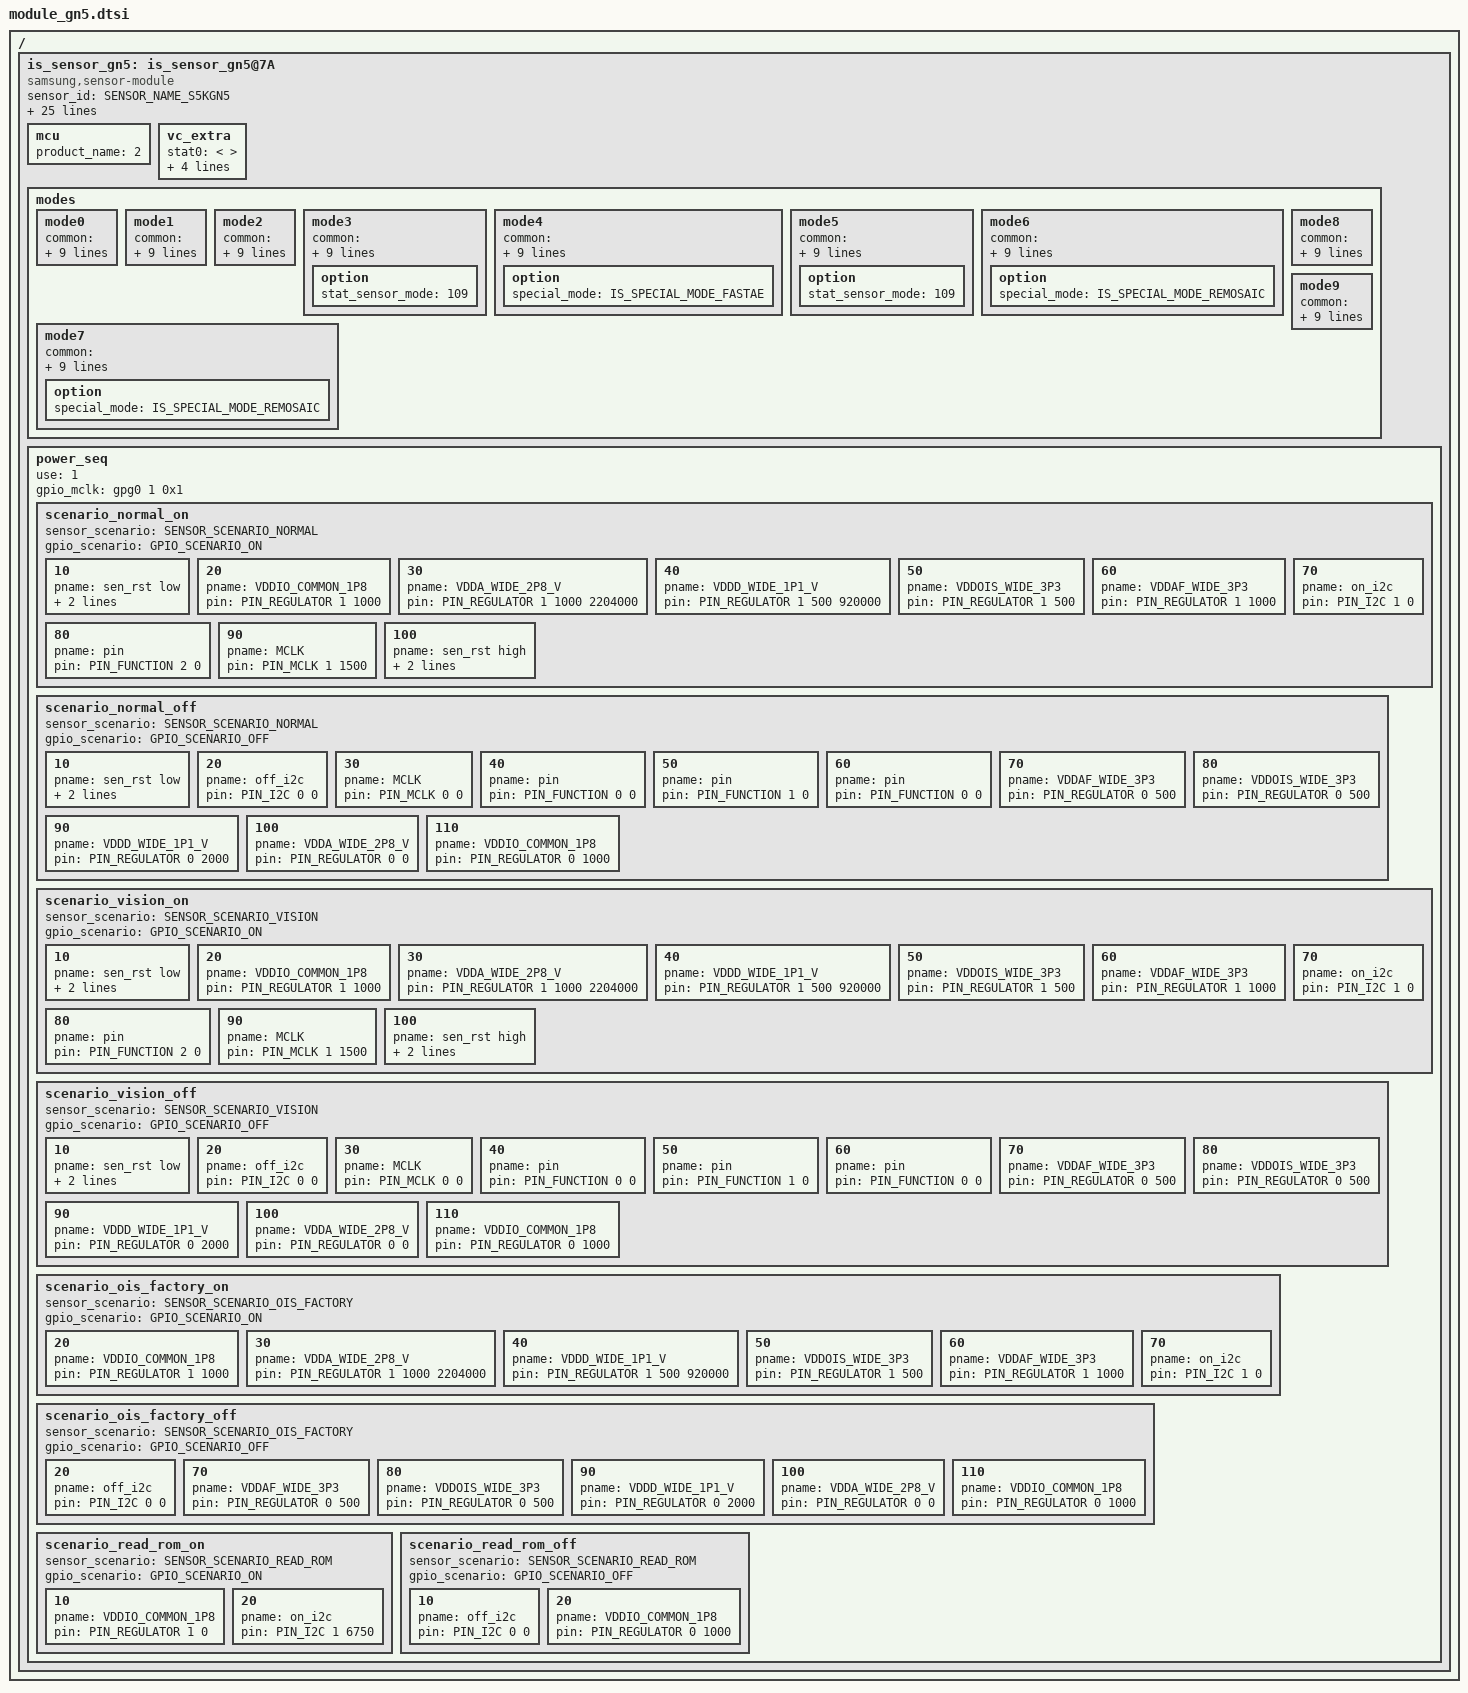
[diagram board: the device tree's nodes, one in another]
/*
 * SAMSUNG EXYNOSxxxx board camera device tree source
 *
 * Copyright (c) 2023 Samsung Electronics Co., Ltd.
 *		http://www.samsung.com
 *
 * This program is free software; you can redistribute it and/or modify
 * it under the terms of the GNU General Public License version 2 as
 * published by the Free Software Foundation.
 */

#include <dt-bindings/camera/exynos_is_dt.h>

/ {
	fragment@camera {
		target-path = "/";
		__overlay__ {
			is_sensor_gn5: is_sensor_gn5@7A {
				compatible = "samsung,sensor-module";

				/* common */
				sensor_id = <SENSOR_NAME_S5KGN5>;
				active_width = <8160>;
				active_height = <6120>;
				margin_left = <0>;
				margin_right = <0>;
				margin_top = <0>;
				margin_bottom = <0>;
				max_framerate = <480>;
				bitwidth = <10>;
				use_retention_mode = <SENSOR_RETENTION_UNSUPPORTED>;
				sensor_maker = "SLSI";
				sensor_name = "S5KGN5";
				setfile_name = "setfile_gn5.bin";

				status = "okay";

				/* board */
				pinctrl-names = "pin0", "pin1", "pin2", "release";
				pinctrl-0 = <>;
				pinctrl-1 = <&sensor_mclk0_out>;
				pinctrl-2 = <&sensor_mclk0_fn>;
				pinctrl-3 = <>;

				position = <0>; /* sensor position of camera dt */
				id = <0>; /* is_sensor id */
				mclk_ch = <0>;
				mclk_freq = <19200>;
				sensor_i2c_ch = <0>; /* SENSOR_CONTROL_I2C0 lock */

				/* vendor */
				rom_type = <2>; /* ROM_TYPE_EEPROM */
				rom_id = <0>;
				rom_cal_index = <0>;

				mcu {
					product_name = <2>; /* MCU_NAME_INTERNAL */
				};

				vc_extra {
					/* ex) statX = <stat_type, sensor_mode, max_width, max_height, max_element> */
					stat0 = </* not available */>;									/* VC_BUF_DATA_TYPE_SENSOR_STAT1 */
					stat1 = </*VC_STAT_TYPE_PDP_4_1_PDAF_STAT0*/ 1200 /*VC_SENSOR_MODE_2PD_MODE3*/ 102 4080 764 2>;	/* VC_BUF_DATA_TYPE_GENERAL_STAT1 */
					stat2 = </* not available */>;									/* VC_BUF_DATA_TYPE_SENSOR_STAT2 */
					stat3 = </*VC_STAT_TYPE_PDP_4_1_PDAF_STAT1*/ 1201 /*VC_SENSOR_MODE_2PD_MODE3*/ 102 4080 764 2>;	/* VC_BUF_DATA_TYPE_GENERAL_STAT2 */
					stat_vc = <2>; /* STAT out VC after CSIS link */
				};

				/* sensor modes
				*	SENSOR_GN5_4080x3060_30FPS 12bit(P) = 0,
				*	SENSOR_GN5_4080x2296_30FPS 12bit(P) = 1,
				*	SENSOR_GN5_4080x2296_60FPS 12bit(P) = 2,
				*	SENSOR_GN5_2040x1532_30FPS 10bit = 3,
				*	SENSOR_GN5_2040x1532_120FPS 10bit = 4,
				*	SENSOR_GN5_2040x1148_240FPS 10bit = 5,
				*	SENSOR_GN5_8160x6120_24FPS 10bit = 6,
				*	SENSOR_GN5_8160x4592_24FPS 10bit = 7,
				*	SENSOR_GN5_4080X3060_30FPS_IDCG_R12 = 8,
				*	SENSOR_GN5_4080X2296_30FPS_IDCG_R12 = 9,
				*/
				modes {
						/* common = <width, height, fps, settle, mode, lane, speed, interleave, lrte, pd_mode> */
						/* vcX = <map, hwformat, width, height, hwformat, type, width, height> */
					mode0 { /* SENSOR_GN5_4080X3060_30FPS_R12 */
						common = <4080 3060 30 0 0 CSI_DATA_LANES_3 2969 CSI_MODE_VC_DT LRTE_ENABLE PD_MOD3 EX_NONE>;
						vc0 = </* in */ 0 HW_FORMAT_RAW12 DATA_IMG 4080 3060    /* out */ HW_FORMAT_RAW12 VC_NOTHING 4080 3060>;
						vc1 = </* in */ 1 HW_FORMAT_UNKNOWN DATA_NONE 0 0        /* out */ HW_FORMAT_UNKNOWN VC_NOTHING 0 0>;
						vc2 = </* in */ 2 HW_FORMAT_RAW10_POTF DATA_HPD 4080 764  /* out */ HW_FORMAT_RAW10 VC_NOTHING 0 0>;
						vc3 = </* in */ 3 HW_FORMAT_UNKNOWN DATA_NONE 0 0        /* out */ HW_FORMAT_UNKNOWN VC_NOTHING 0 0>;
					};
					mode1 { /* SENSOR_GN5_4080X2296_30FPS_R12 */
						common = <4080 2296 30 0 1 CSI_DATA_LANES_3 2969 CSI_MODE_VC_DT LRTE_ENABLE PD_MOD3 EX_NONE>;
						vc0 = </* in */ 0 HW_FORMAT_RAW12 DATA_IMG 4080 2296    /* out */ HW_FORMAT_RAW12 VC_NOTHING 4080 2296>;
						vc1 = </* in */ 1 HW_FORMAT_UNKNOWN DATA_NONE 0 0        /* out */ HW_FORMAT_UNKNOWN VC_NOTHING 0 0>;
						vc2 = </* in */ 2 HW_FORMAT_RAW10_POTF DATA_HPD 4080 574  /* out */ HW_FORMAT_RAW10 VC_NOTHING 0 0>;
						vc3 = </* in */ 3 HW_FORMAT_UNKNOWN DATA_NONE 0 0        /* out */ HW_FORMAT_UNKNOWN VC_NOTHING 0 0>;
					};
					mode2 { /* SENSOR_GN5_4080X2296_60FPS_R12 */
						common = <4080 2296 60 0 2 CSI_DATA_LANES_3 2969 CSI_MODE_VC_DT LRTE_ENABLE PD_MOD3 EX_NONE>;
						vc0 = </* in */ 0 HW_FORMAT_RAW12 DATA_IMG 4080 2296    /* out */ HW_FORMAT_RAW12 VC_NOTHING 4080 2296>;
						vc1 = </* in */ 1 HW_FORMAT_UNKNOWN DATA_NONE 0 0        /* out */ HW_FORMAT_UNKNOWN VC_NOTHING 0 0>;
						vc2 = </* in */ 2 HW_FORMAT_RAW10_POTF DATA_HPD 4080 574  /* out */ HW_FORMAT_RAW10 VC_NOTHING 0 0>;
						vc3 = </* in */ 3 HW_FORMAT_UNKNOWN DATA_NONE 0 0        /* out */ HW_FORMAT_UNKNOWN VC_NOTHING 0 0>;
					};
					mode3 { /* SENSOR_GN5_2040X1532_30FPS_R10 */
						common = <2040 1532 30 0 3 CSI_DATA_LANES_3 2508 CSI_MODE_VC_DT LRTE_ENABLE PD_MOD3 EX_NONE>;
						vc0 = </* in */ 0 HW_FORMAT_RAW10 DATA_IMG 2040 1532    /* out */ HW_FORMAT_RAW10 VC_NOTHING 2040 1532>;
						vc1 = </* in */ 1 HW_FORMAT_UNKNOWN DATA_NONE 0 0        /* out */ HW_FORMAT_UNKNOWN VC_NOTHING 0 0>;
						vc2 = </* in */ 2 HW_FORMAT_RAW10_POTF DATA_HPD 2032 382  /* out */ HW_FORMAT_RAW10 VC_NOTHING 0 0>;
						vc3 = </* in */ 3 HW_FORMAT_UNKNOWN DATA_NONE 0 0        /* out */ HW_FORMAT_UNKNOWN VC_NOTHING 0 0>;
						option { stat_sensor_mode = <109>; };
					};
					mode4 { /* SENSOR_GN5_2040X1532_120FPS_R10 */
						common = <2040 1532 120 0 4 CSI_DATA_LANES_3 2508 CSI_MODE_VC_DT LRTE_ENABLE PD_NONE EX_NONE>;
						vc0 = </* in */ 0 HW_FORMAT_RAW10 DATA_IMG 2040 1532    /* out */ HW_FORMAT_RAW10 VC_NOTHING 2040 1532>;
						vc1 = </* in */ 1 HW_FORMAT_UNKNOWN DATA_NONE 0 0        /* out */ HW_FORMAT_UNKNOWN VC_NOTHING 0 0>;
						vc2 = </* in */ 2 HW_FORMAT_UNKNOWN DATA_NONE 0 0    /* out */ HW_FORMAT_UNKNOWN VC_NOTHING 0 0>;
						vc3 = </* in */ 3 HW_FORMAT_UNKNOWN DATA_NONE 0 0        /* out */ HW_FORMAT_UNKNOWN VC_NOTHING 0 0>;
						option { special_mode = <IS_SPECIAL_MODE_FASTAE>; };
					};
					mode5 { /* SENSOR_GN5_2040X1148_240FPS_R10 */
						common = <2040 1148 240 0 5 CSI_DATA_LANES_3 2508 CSI_MODE_VC_DT LRTE_ENABLE PD_MOD3 EX_NONE>;
						vc0 = </* in */ 0 HW_FORMAT_RAW10 DATA_IMG 2040 1148    /* out */ HW_FORMAT_RAW10 VC_NOTHING 2040 1148>;
						vc1 = </* in */ 1 HW_FORMAT_UNKNOWN DATA_NONE 0 0        /* out */ HW_FORMAT_UNKNOWN VC_NOTHING 0 0>;
						vc2 = </* in */ 2 HW_FORMAT_RAW10_POTF DATA_HPD 2032 286  /* out */ HW_FORMAT_RAW10 VC_NOTHING 0 0>;
						vc3 = </* in */ 3 HW_FORMAT_UNKNOWN DATA_NONE 0 0        /* out */ HW_FORMAT_UNKNOWN VC_NOTHING 0 0>;
						option { stat_sensor_mode = <109>; };
					};
					mode6 { /* SENSOR_GN5_8160X6120_24FPS */
						common = <8160 6120 24 0 6 CSI_DATA_LANES_3 2969 CSI_MODE_VC_DT LRTE_ENABLE PD_NONE EX_NONE>;
						vc0 = </* in */ 0 HW_FORMAT_RAW10 DATA_IMG 8160 6120    /* out */ HW_FORMAT_RAW10 VC_NOTHING 8160 6120>;
						vc1 = </* in */ 1 HW_FORMAT_UNKNOWN DATA_NONE 0 0        /* out */ HW_FORMAT_UNKNOWN VC_NOTHING 0 0>;
						vc2 = </* in */ 2 HW_FORMAT_UNKNOWN DATA_NONE 0 0    /* out */ HW_FORMAT_UNKNOWN VC_NOTHING 0 0>;
						vc3 = </* in */ 3 HW_FORMAT_UNKNOWN DATA_NONE 0 0        /* out */ HW_FORMAT_UNKNOWN VC_NOTHING 0 0>;
						option { special_mode = <IS_SPECIAL_MODE_REMOSAIC>; };
					};
					mode7 { /* SENSOR_GN5_8160X4592_24FPS */
						common = <8160 4592 24 0 7 CSI_DATA_LANES_3 2969 CSI_MODE_VC_DT LRTE_ENABLE PD_NONE EX_NONE>;
						vc0 = </* in */ 0 HW_FORMAT_RAW10 DATA_IMG 8160 4592    /* out */ HW_FORMAT_RAW10 VC_NOTHING 8160 4592>;
						vc1 = </* in */ 1 HW_FORMAT_UNKNOWN DATA_NONE 0 0        /* out */ HW_FORMAT_UNKNOWN VC_NOTHING 0 0>;
						vc2 = </* in */ 2 HW_FORMAT_UNKNOWN DATA_NONE 0 0    /* out */ HW_FORMAT_UNKNOWN VC_NOTHING 0 0>;
						vc3 = </* in */ 3 HW_FORMAT_UNKNOWN DATA_NONE 0 0        /* out */ HW_FORMAT_UNKNOWN VC_NOTHING 0 0>;
						option { special_mode = <IS_SPECIAL_MODE_REMOSAIC>; };
					};
					mode8 { /* SENSOR_GN5_4080X3060_30FPS_IDCG_R12 */
						common = <4080 3060 30 0 8 CSI_DATA_LANES_3 2969 CSI_MODE_VC_DT LRTE_ENABLE PD_MOD3 EX_DCG>;
						vc0 = </* in */ 0 HW_FORMAT_RAW12 DATA_IMG 4080 3060    /* out */ HW_FORMAT_RAW12 VC_NOTHING 4080 3060>;
						vc1 = </* in */ 1 HW_FORMAT_UNKNOWN DATA_NONE 0 0        /* out */ HW_FORMAT_UNKNOWN VC_NOTHING 0 0>;
						vc2 = </* in */ 2 HW_FORMAT_RAW10_POTF DATA_HPD 4080 764  /* out */ HW_FORMAT_RAW10 VC_NOTHING 0 0>;
						vc3 = </* in */ 3 HW_FORMAT_UNKNOWN DATA_NONE 0 0        /* out */ HW_FORMAT_UNKNOWN VC_NOTHING 0 0>;
					};
					mode9 { /* SENSOR_GN5_4080X2296_30FPS_IDCG_R12 */
						common = <4080 2296 30 0 9 CSI_DATA_LANES_3 2969 CSI_MODE_VC_DT LRTE_ENABLE PD_MOD3 EX_DCG>;
						vc0 = </* in */ 0 HW_FORMAT_RAW12 DATA_IMG 4080 2296    /* out */ HW_FORMAT_RAW12 VC_NOTHING 4080 2296>;
						vc1 = </* in */ 1 HW_FORMAT_UNKNOWN DATA_NONE 0 0        /* out */ HW_FORMAT_UNKNOWN VC_NOTHING 0 0>;
						vc2 = </* in */ 2 HW_FORMAT_RAW10_POTF DATA_HPD 4080 574  /* out */ HW_FORMAT_RAW10 VC_NOTHING 0 0>;
						vc3 = </* in */ 3 HW_FORMAT_UNKNOWN DATA_NONE 0 0        /* out */ HW_FORMAT_UNKNOWN VC_NOTHING 0 0>;
					};
				};

				power_seq {
					use = <1>;
					gpio_mclk = <&gpg0 1 0x1>;
					scenario_normal_on {
						sensor_scenario = <SENSOR_SCENARIO_NORMAL>;
						gpio_scenario = <GPIO_SCENARIO_ON>;

						/* A start node number should be over the 10 for reserved number 0~9. */
						/* pname = "name"; pin = <act value delay voltage>; gpio = <gpx# # 0x1>; */
						10 { pname = "sen_rst low"; pin = <PIN_OUTPUT 0 0>; gpio = <&gpg2 1 0x1>; };
						20 { pname = "VDDIO_COMMON_1P8"; pin = <PIN_REGULATOR 1 1000>; };
						30 { pname = "VDDA_WIDE_2P8_V"; pin = <PIN_REGULATOR 1 1000 2204000>; };
						40 { pname = "VDDD_WIDE_1P1_V"; pin = <PIN_REGULATOR 1 500 920000>; };
						50 { pname = "VDDOIS_WIDE_3P3"; pin = <PIN_REGULATOR 1 500>; };
						60 { pname = "VDDAF_WIDE_3P3"; pin = <PIN_REGULATOR 1 1000>; };
						70 { pname = "on_i2c"; pin = <PIN_I2C 1 0>; };
						80 { pname = "pin"; pin = <PIN_FUNCTION 2 0>; };
						90 { pname = "MCLK"; pin = <PIN_MCLK 1 1500>; };
						100 { pname = "sen_rst high"; pin = <PIN_OUTPUT 1 8000>; gpio = <&gpg2 1 0x1>; };
					};

					scenario_normal_off {
						sensor_scenario = <SENSOR_SCENARIO_NORMAL>;
						gpio_scenario = <GPIO_SCENARIO_OFF>;

						/* A start node number should be over the 10 for reserved number 0~9. */
						/* pname = "name"; pin = <act value dealy voltage>; gpio = <gpx# # 0x1>; */
						10 { pname = "sen_rst low"; pin = <PIN_OUTPUT 0 1000>; gpio = <&gpg2 1 0x1>;};
						20 { pname = "off_i2c"; pin = <PIN_I2C 0 0>; };
						30 { pname = "MCLK"; pin = <PIN_MCLK 0 0>; };
						40 { pname = "pin"; pin = <PIN_FUNCTION 0 0>; };
						50 { pname = "pin"; pin = <PIN_FUNCTION 1 0>; };
						60 { pname = "pin"; pin = <PIN_FUNCTION 0 0>; };
						70 { pname = "VDDAF_WIDE_3P3"; pin = <PIN_REGULATOR 0 500>; };
						80 { pname = "VDDOIS_WIDE_3P3"; pin = <PIN_REGULATOR 0 500>; };
						90 { pname = "VDDD_WIDE_1P1_V"; pin = <PIN_REGULATOR 0 2000>; };
						100 { pname = "VDDA_WIDE_2P8_V"; pin = <PIN_REGULATOR 0 0>; };
						110 { pname = "VDDIO_COMMON_1P8"; pin = <PIN_REGULATOR 0 1000>; };
					};

					scenario_vision_on {
						sensor_scenario = <SENSOR_SCENARIO_VISION>;
						gpio_scenario = <GPIO_SCENARIO_ON>;

						/* A start node number should be over the 10 for reserved number 0~9. */
						/* pname = "name"; pin = <act value delay voltage>; gpio = <gpx# # 0x1>; */
						10 { pname = "sen_rst low"; pin = <PIN_OUTPUT 0 0>; gpio = <&gpg2 1 0x1>; };
						20 { pname = "VDDIO_COMMON_1P8"; pin = <PIN_REGULATOR 1 1000>; };
						30 { pname = "VDDA_WIDE_2P8_V"; pin = <PIN_REGULATOR 1 1000 2204000>; };
						40 { pname = "VDDD_WIDE_1P1_V"; pin = <PIN_REGULATOR 1 500 920000>; };
						50 { pname = "VDDOIS_WIDE_3P3"; pin = <PIN_REGULATOR 1 500>; };
						60 { pname = "VDDAF_WIDE_3P3"; pin = <PIN_REGULATOR 1 1000>; };
						70 { pname = "on_i2c"; pin = <PIN_I2C 1 0>; };
						80 { pname = "pin"; pin = <PIN_FUNCTION 2 0>; };
						90 { pname = "MCLK"; pin = <PIN_MCLK 1 1500>; };
						100 { pname = "sen_rst high"; pin = <PIN_OUTPUT 1 8000>; gpio = <&gpg2 1 0x1>; };
					};

					scenario_vision_off {
						sensor_scenario = <SENSOR_SCENARIO_VISION>;
						gpio_scenario = <GPIO_SCENARIO_OFF>;
						/* A start node number should be over the 10 for reserved number 0~9. */
						/* pname = "name"; pin = <act value dealy voltage>; gpio = <gpx# # 0x1>; */
						10 { pname = "sen_rst low"; pin = <PIN_OUTPUT 0 1000>; gpio = <&gpg2 1 0x1>;};
						20 { pname = "off_i2c"; pin = <PIN_I2C 0 0>; };
						30 { pname = "MCLK"; pin = <PIN_MCLK 0 0>; };
						40 { pname = "pin"; pin = <PIN_FUNCTION 0 0>; };
						50 { pname = "pin"; pin = <PIN_FUNCTION 1 0>; };
						60 { pname = "pin"; pin = <PIN_FUNCTION 0 0>; };
						70 { pname = "VDDAF_WIDE_3P3"; pin = <PIN_REGULATOR 0 500>; };
						80 { pname = "VDDOIS_WIDE_3P3"; pin = <PIN_REGULATOR 0 500>; };
						90 { pname = "VDDD_WIDE_1P1_V"; pin = <PIN_REGULATOR 0 2000>; };
						100 { pname = "VDDA_WIDE_2P8_V"; pin = <PIN_REGULATOR 0 0>; };
						110 { pname = "VDDIO_COMMON_1P8"; pin = <PIN_REGULATOR 0 1000>; };
					};

					scenario_ois_factory_on {
						sensor_scenario = <SENSOR_SCENARIO_OIS_FACTORY>;
						gpio_scenario = <GPIO_SCENARIO_ON>;

						/* A start node number should be over the 10 for reserved number 0~9. */
						/* pname = "name"; pin = <act value delay voltage>; gpio = <gpx# # 0x1>; */
						20 { pname = "VDDIO_COMMON_1P8"; pin = <PIN_REGULATOR 1 1000>; };
						30 { pname = "VDDA_WIDE_2P8_V"; pin = <PIN_REGULATOR 1 1000 2204000>; };
						40 { pname = "VDDD_WIDE_1P1_V"; pin = <PIN_REGULATOR 1 500 920000>; };
						50 { pname = "VDDOIS_WIDE_3P3"; pin = <PIN_REGULATOR 1 500>; };
						60 { pname = "VDDAF_WIDE_3P3"; pin = <PIN_REGULATOR 1 1000>; };
						70 { pname = "on_i2c"; pin = <PIN_I2C 1 0>; };
					};

					scenario_ois_factory_off {
						sensor_scenario = <SENSOR_SCENARIO_OIS_FACTORY>;
						gpio_scenario = <GPIO_SCENARIO_OFF>;

						/* A start node number should be over the 10 for reserved number 0~9. */
						/* pname = "name"; pin = <act value delay voltage>; gpio = <gpx# # 0x1>; */
						20 { pname = "off_i2c"; pin = <PIN_I2C 0 0>; };
						70 { pname = "VDDAF_WIDE_3P3"; pin = <PIN_REGULATOR 0 500>; };
						80 { pname = "VDDOIS_WIDE_3P3"; pin = <PIN_REGULATOR 0 500>; };
						90 { pname = "VDDD_WIDE_1P1_V"; pin = <PIN_REGULATOR 0 2000>; };
						100 { pname = "VDDA_WIDE_2P8_V"; pin = <PIN_REGULATOR 0 0>; };
						110 { pname = "VDDIO_COMMON_1P8"; pin = <PIN_REGULATOR 0 1000>; };
					};

					scenario_read_rom_on {
						sensor_scenario = <SENSOR_SCENARIO_READ_ROM>;
						gpio_scenario = <GPIO_SCENARIO_ON>;

						/* A start node number should be over the 10 for reserved number 0~9. */
						/* pname = "name"; pin = <act value dealy voltage>; gpio = <gpx# # 0x1>; */
						10 { pname = "VDDIO_COMMON_1P8"; pin = <PIN_REGULATOR 1 0>; };
						20 { pname = "on_i2c"; pin = <PIN_I2C 1 6750>; };
						
					};

					scenario_read_rom_off {
						sensor_scenario = <SENSOR_SCENARIO_READ_ROM>;
						gpio_scenario = <GPIO_SCENARIO_OFF>;

						/* A start node number should be over the 10 for reserved number 0~9. */
						/* pname = "name"; pin = <act value dealy voltage>; gpio = <gpx# # 0x1>; */
						10 { pname = "off_i2c"; pin = <PIN_I2C 0 0>; };
						20 { pname = "VDDIO_COMMON_1P8"; pin = <PIN_REGULATOR 0 1000>; };
					};
				};
			};
		}; /* end of __overlay__ */
	}; /* end of fragment */
}; /* end of root */
